# MIMXRT1041 register map
Vendor: nxp.com; File version: 1.0
CPU: CM7 r0p1, little endian, MPU, FPU, VTOR, 4 interrupt priority bits
Registers are 32-bit, read-write, reset 0x0 unless marked. A register's access mark holds for its fields unless they carry their own. Offsets are from the block's base; [hi:lo] are bit positions; lines under a group give offsets from that group; {n}, {i} and the like mark numbered series; 'fields as' and 'values as' point back to an identical list.

## AIPSTZ1 — AIPSTZ Control Registers
Base 0x4007C000; register names take the prefix AIPSTZ1_
Same registers: AIPSTZ2 0x4017C000 (register names take the prefix AIPSTZ2_), AIPSTZ3 0x4027C000 (register names take the prefix AIPSTZ3_), AIPSTZ4 0x4037C000 (register names take the prefix AIPSTZ4_)
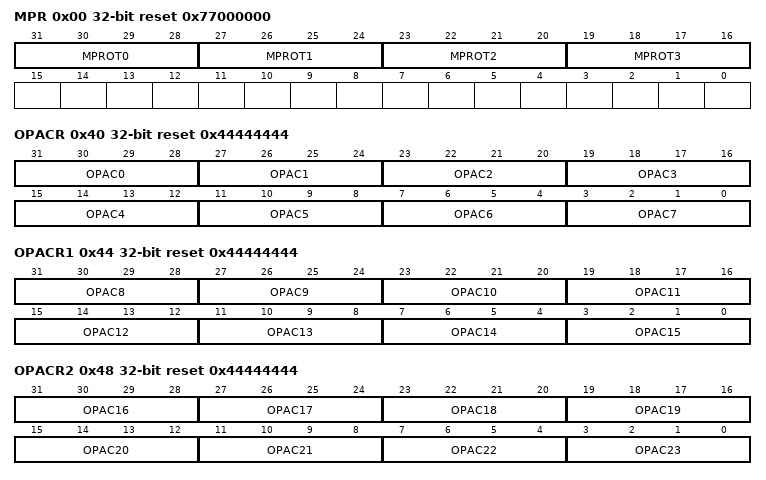
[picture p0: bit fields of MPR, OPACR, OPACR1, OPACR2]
0x00 MPR reset 0x77000000 — Master Priviledge Registers
  [all] fields
    0bxxx0=MPL0 (Accesses from this master are forced to user-mode (ips_supervisor_access is forced to zero) regardless of the hprot[1] access attribute.); 0bxxx1=MPL1 (Accesses from this master are not forced to user-mode. The hprot[1] access attribute is used directly to determine ips_supervisor_access.)
  [31:28] MPROT0 — Master 0 Priviledge, Buffer, Read, Write Control
  [27:24] MPROT1 — Master 1 Priviledge, Buffer, Read, Write Control
  [23:20] MPROT2 — Master 2 Priviledge, Buffer, Read, Write Control
  [19:16] MPROT3 — Master 3 Priviledge, Buffer, Read, Write Control.
0x40 OPACR reset 0x44444444 — Off-Platform Peripheral Access Control Registers
  [all] fields
    0bxxx0=TP0 (Accesses from an untrusted master are allowed.); 0bxxx1=TP1 (Accesses from an untrusted master are not allowed. If an access is attempted by an untrusted master, the access is terminated with an error response and no peripheral access is initiated on the IPS bus.)
  [31-4n:28-4n] OPAC{n} (n=0..7) — Off-platform Peripheral Access Control {n}
0x44 OPACR1 reset 0x44444444 — Off-Platform Peripheral Access Control Registers
  [all] fields
    values as the fields of OPACR
  [63-4n:60-4n] OPAC{n} (n=8..15) — Off-platform Peripheral Access Control {n}
0x48 OPACR2 reset 0x44444444 — Off-Platform Peripheral Access Control Registers
  [all] fields
    values as the fields of OPACR
  [95-4n:92-4n] OPAC{n} (n=16..23) — Off-platform Peripheral Access Control {n}
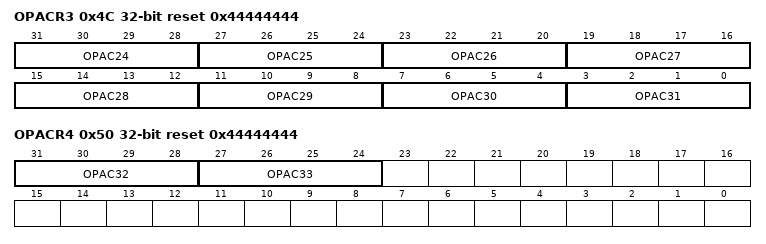
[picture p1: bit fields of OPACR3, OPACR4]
0x4C OPACR3 reset 0x44444444 — Off-Platform Peripheral Access Control Registers
  [all] fields
    values as the fields of OPACR
  [127-4n:124-4n] OPAC{n} (n=24..31) — Off-platform Peripheral Access Control {n}
0x50 OPACR4 reset 0x44444444 — Off-Platform Peripheral Access Control Registers
  [31:28] OPAC32 — Off-platform Peripheral Access Control 32
    values as the fields of OPACR
  [27:24] OPAC33 — Off-platform Peripheral Access Control 33
    values as the fields of OPACR

## PIT
Base 0x40084000
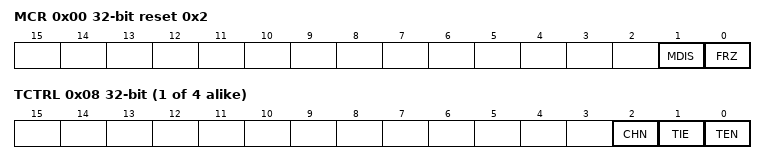
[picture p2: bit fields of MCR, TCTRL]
0x00 MCR reset 0x2 — PIT Module Control Register
  [1] MDIS — Module Disable for PIT
    0=t0301 (Clock for standard PIT timers is enabled.); 1=t00000111 (Clock for standard PIT timers is disabled.)
  [0] FRZ — Freeze
    0=t000001 (Timers continue to run in Debug mode.); 1=t0000011 (Timers are stopped in Debug mode.)
0xE0 LTMR64H ro — PIT Upper Lifetime Timer Register
  [31:0] LTH — Life Timer value
0xE4 LTMR64L ro — PIT Lower Lifetime Timer Register
  [31:0] LTL — Life Timer value
{0x100+0x10*i} TIMER[{i}] (i=0..3) group — Timer array.
  0x00 LDVAL — Timer Load Value Register
    [31:0] TSV — Timer Start Value
  0x04 CVAL ro — Current Timer Value Register
    [31:0] TVL — Current Timer Value
  0x08 TCTRL — Timer Control Register
    [2] CHN — Chain Mode
      0=timer0001 (Timer is not chained.); 1=timer0081 (Timer is chained to a previous timer. For example, for channel 2, if this field is set, Timer 2 is chained to Timer 1.)
    [1] TIE — Timer Interrupt Enable
      0=t0331 (Interrupt requests from Timer n are disabled.); 1=t077711 (Interrupt is requested whenever TIF is set.)
    [0] TEN — Timer Enable
      0=t02981 (Timer n is disabled.); 1=t008981 (Timer n is enabled.)
  0x0C TFLG write-1-clears — Timer Flag Register
    [0] TIF write-1-clears — Timer Interrupt Flag
      0=t0022331 (Timeout has not yet occurred.); 1=t0022332221 (Timeout has occurred.)

## Notices in the file
Copyright 2016-2022 NXP
All rights reserved.
SPDX-License-Identifier: BSD-3-Clause
